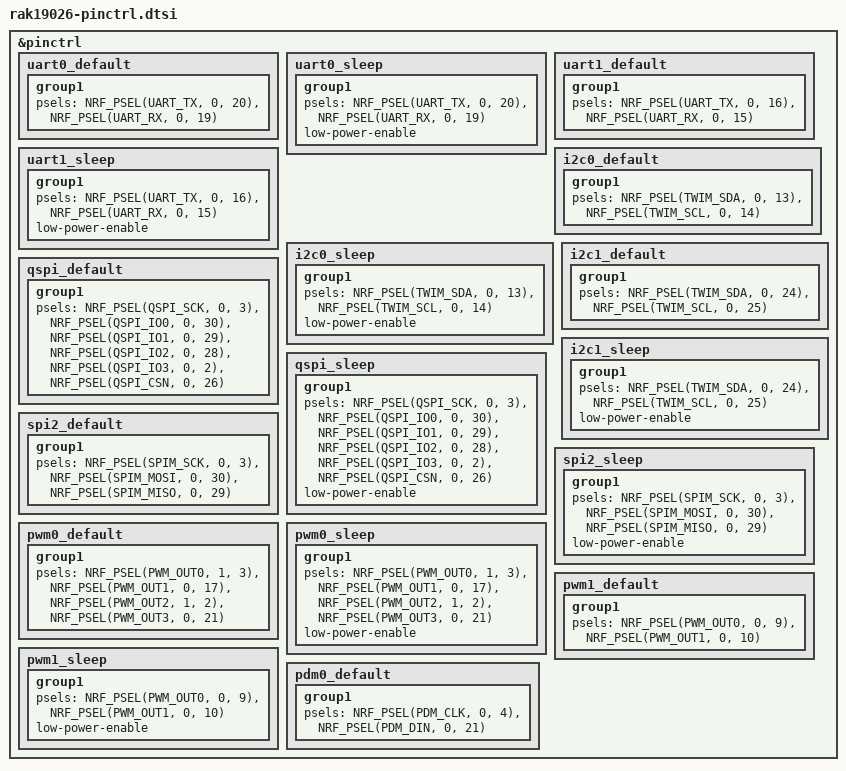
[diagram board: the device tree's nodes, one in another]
/*
 * SPDX-License-Identifier: Apache-2.0
 * Copyright (c) 2026 RAKwireless Technology Co., Ltd.
 */

#include <zephyr/dt-bindings/pinctrl/nrf-pinctrl.h>

&pinctrl {
	uart0_default: uart0_default {
		group1 {
			psels = <NRF_PSEL(UART_TX, 0, 20)>,
				<NRF_PSEL(UART_RX, 0, 19)>;
		};
	};

	uart0_sleep: uart0_sleep {
		group1 {
			psels = <NRF_PSEL(UART_TX, 0, 20)>,
				<NRF_PSEL(UART_RX, 0, 19)>;
			low-power-enable;
		};
	};

	uart1_default: uart1_default {
		group1 {
			psels = <NRF_PSEL(UART_TX, 0, 16)>,
				<NRF_PSEL(UART_RX, 0, 15)>;
		};
	};

	uart1_sleep: uart1_sleep {
		group1 {
			psels = <NRF_PSEL(UART_TX, 0, 16)>,
				<NRF_PSEL(UART_RX, 0, 15)>;
			low-power-enable;
		};
	};

	i2c0_default: i2c0_default {
		group1 {
			psels = <NRF_PSEL(TWIM_SDA, 0, 13)>,
				<NRF_PSEL(TWIM_SCL, 0, 14)>;
		};
	};

	i2c0_sleep: i2c0_sleep {
		group1 {
			psels = <NRF_PSEL(TWIM_SDA, 0, 13)>,
				<NRF_PSEL(TWIM_SCL, 0, 14)>;
			low-power-enable;
		};
	};

	i2c1_default: i2c1_default {
		group1 {
			psels = <NRF_PSEL(TWIM_SDA, 0, 24)>,
				<NRF_PSEL(TWIM_SCL, 0, 25)>;
		};
	};

	i2c1_sleep: i2c1_sleep {
		group1 {
			psels = <NRF_PSEL(TWIM_SDA, 0, 24)>,
				<NRF_PSEL(TWIM_SCL, 0, 25)>;
			low-power-enable;
		};
	};

	qspi_default: qspi_default {
		group1 {
			psels = <NRF_PSEL(QSPI_SCK, 0, 3)>,
				<NRF_PSEL(QSPI_IO0, 0, 30)>,
				<NRF_PSEL(QSPI_IO1, 0, 29)>,
				<NRF_PSEL(QSPI_IO2, 0, 28)>,
				<NRF_PSEL(QSPI_IO3, 0, 2)>,
				<NRF_PSEL(QSPI_CSN, 0, 26)>;
		};
	};

	qspi_sleep: qspi_sleep {
		group1 {
			psels = <NRF_PSEL(QSPI_SCK, 0, 3)>,
				<NRF_PSEL(QSPI_IO0, 0, 30)>,
				<NRF_PSEL(QSPI_IO1, 0, 29)>,
				<NRF_PSEL(QSPI_IO2, 0, 28)>,
				<NRF_PSEL(QSPI_IO3, 0, 2)>,
				<NRF_PSEL(QSPI_CSN, 0, 26)>;
			low-power-enable;
		};
	};

	spi2_default: spi2_default {
		group1 {
			psels = <NRF_PSEL(SPIM_SCK, 0, 3)>,
				<NRF_PSEL(SPIM_MOSI, 0, 30)>,
				<NRF_PSEL(SPIM_MISO, 0, 29)>;
		};
	};

	spi2_sleep: spi2_sleep {
		group1 {
			psels = <NRF_PSEL(SPIM_SCK, 0, 3)>,
				<NRF_PSEL(SPIM_MOSI, 0, 30)>,
				<NRF_PSEL(SPIM_MISO, 0, 29)>;
			low-power-enable;
		};
	};

	pwm0_default: pwm0_default {
		group1 {
			psels = <NRF_PSEL(PWM_OUT0, 1, 3)>,
				<NRF_PSEL(PWM_OUT1, 0, 17)>,
				<NRF_PSEL(PWM_OUT2, 1, 2)>,
				<NRF_PSEL(PWM_OUT3, 0, 21)>;
		};
	};

	pwm0_sleep: pwm0_sleep {
		group1 {
			psels = <NRF_PSEL(PWM_OUT0, 1, 3)>,
				<NRF_PSEL(PWM_OUT1, 0, 17)>,
				<NRF_PSEL(PWM_OUT2, 1, 2)>,
				<NRF_PSEL(PWM_OUT3, 0, 21)>;
			low-power-enable;
		};
	};

	pwm1_default: pwm1_default {
		group1 {
			psels = <NRF_PSEL(PWM_OUT0, 0, 9)>,
				<NRF_PSEL(PWM_OUT1, 0, 10)>;
		};
	};

	pwm1_sleep: pwm1_sleep {
		group1 {
			psels = <NRF_PSEL(PWM_OUT0, 0, 9)>,
				<NRF_PSEL(PWM_OUT1, 0, 10)>;
			low-power-enable;
		};
	};

	pdm0_default: pdm0_default {
		group1 {
			psels = <NRF_PSEL(PDM_CLK, 0, 4)>,
				<NRF_PSEL(PDM_DIN, 0, 21)>;
		};
	};
};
